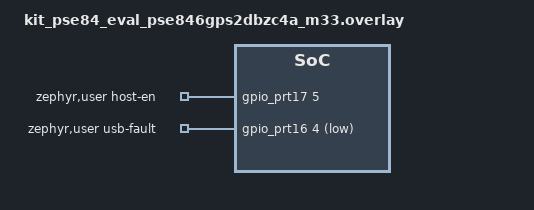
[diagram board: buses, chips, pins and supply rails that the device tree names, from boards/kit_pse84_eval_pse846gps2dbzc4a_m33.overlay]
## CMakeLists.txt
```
# SPDX-License-Identifier: Apache-2.0

cmake_minimum_required(VERSION 3.20.0)

find_package(Zephyr REQUIRED HINTS $ENV{ZEPHYR_BASE})
project(tinyusb_host_cdc_msc_hid)

# Application sources. This sample is fully Zephyr-native: the USBHS controller
# interrupt is connected by the ifx-tinyusb module
target_sources(app PRIVATE
  src/main.c
  src/cdc_app.c
  src/hid_app.c
  src/msc_app.c
)

target_include_directories(app PRIVATE
  src
)

# tusb_config.h lives in this sample's src/. It must also be visible to the
# TinyUSB module sources, which are compiled in the module's own CMake scope,
# so expose it on the global include path.
zephyr_include_directories(${CMAKE_CURRENT_SOURCE_DIR}/src)
```

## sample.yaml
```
sample:
  description: TinyUSB host CDC/MSC/HID example
  name: tinyusb host cdc_msc_hid
common:
  tags:
    - usb
    - tinyusb
    - host
    - samples
  modules:
    - tinyusb
tests:
  sample.usb.tinyusb.host.cdc_msc_hid:
    harness: none
    platform_allow:
      - kit_pse84_eval/pse846gps2dbzc4a/m33
    integration_platforms:
      - kit_pse84_eval/pse846gps2dbzc4a/m33
```

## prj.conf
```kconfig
# TinyUSB host example: CDC + MSC + HID
#
# Drives the TinyUSB Zephyr module (CONFIG_TINYUSB). The tusb_config.h in src/
# selects the host classes; the controller port is selected by Kconfig.

# Enable the TinyUSB module and the Infineon DWC2 (PSE84 high-speed) port.
CONFIG_TINYUSB=y
CONFIG_TINYUSB_PORT_DWC2_IFX=y

# Let the TinyUSB module connect the USBHS controller interrupt from devicetree
CONFIG_TINYUSB_DWC2_IFX_IRQ_CONNECT=y

CONFIG_GPIO=y
CONFIG_FPU=y

# The class app tasks run in the main thread (tuh_task() has its own thread);
# give the main stack headroom for descriptor parsing and control transfers.
CONFIG_MAIN_STACK_SIZE=4096
```

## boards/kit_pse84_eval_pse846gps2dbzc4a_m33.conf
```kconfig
# PSE84 secure m33 - TinyUSB provides its own host stack, so keep Zephyr's USB
# host/device stacks and their controller drivers disabled to avoid claiming
# the usbhs (DWC2) controller.
CONFIG_USB_HOST_STACK=n
CONFIG_UHC_DRIVER=n
CONFIG_USB_DEVICE_STACK=n
CONFIG_UDC_DRIVER=n
```

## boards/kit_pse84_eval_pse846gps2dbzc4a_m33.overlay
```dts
/*
 * KIT_PSE84_EVAL USB Host (Type-A connector J27) control signals.
 *
 * USB_HOST_EN (P17[5]) gates the USB mux (U25) and the VBUS_HOST power switch
 * (U21/U22). Driving it high switches the data lines to J27 and turns on the
 * 5V host VBUS. USB_FAULT (P16[4], active-low) flags a host VBUS overcurrent.
 *
 * The PSE84 GPIO port controllers are disabled by default, so enable the ports
 * used here and expose the pins to main.c through the zephyr,user node.
 */
#include <zephyr/dt-bindings/gpio/gpio.h>

&gpio_prt16 {
	status = "okay";
};

&gpio_prt17 {
	status = "okay";
};

/ {
	zephyr,user {
		host-en-gpios = <&gpio_prt17 5 GPIO_ACTIVE_HIGH>;
		usb-fault-gpios = <&gpio_prt16 4 GPIO_ACTIVE_LOW>;
	};
};
```

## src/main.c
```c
/*
 * The MIT License (MIT)
 *
 * Copyright (c) 2019 Ha Thach (tinyusb.org)
 *
 * Permission is hereby granted, free of charge, to any person obtaining a copy
 * of this software and associated documentation files (the "Software"), to deal
 * in the Software without restriction, including without limitation the rights
 * to use, copy, modify, merge, publish, distribute, sublicense, and/or sell
 * copies of the Software, and to permit persons to whom the Software is
 * furnished to do so, subject to the following conditions:
 *
 * The above copyright notice and this permission notice shall be included in
 * all copies or substantial portions of the Software.
 *
 * THE SOFTWARE IS PROVIDED "AS IS", WITHOUT WARRANTY OF ANY KIND, EXPRESS OR
 * IMPLIED, INCLUDING BUT NOT LIMITED TO THE WARRANTIES OF MERCHANTABILITY,
 * FITNESS FOR A PARTICULAR PURPOSE AND NONINFRINGEMENT. IN NO EVENT SHALL THE
 * AUTHORS OR COPYRIGHT HOLDERS BE LIABLE FOR ANY CLAIM, DAMAGES OR OTHER
 * LIABILITY, WHETHER IN AN ACTION OF CONTRACT, TORT OR OTHERWISE, ARISING FROM,
 * OUT OF OR IN CONNECTION WITH THE SOFTWARE OR THE USE OR OTHER DEALINGS IN
 * THE SOFTWARE.
 *
 */

#include <stdio.h>

#include "tusb.h"
#include "app.h"

#include <zephyr/kernel.h>
#include <zephyr/devicetree.h>
#include <zephyr/drivers/gpio.h>

//--------------------------------------------------------------------+
// MACRO CONSTANT TYPEDEF PROTOTYPES
//--------------------------------------------------------------------+
void led_blinking_task(void);

// Run tuh_task() in a dedicated COOPERATIVE (higher-than-main) thread so the
// host event queue is drained promptly even while the main thread is busy in
// blocking console printf (Zephyr uart_poll_out busy-waits and does not yield).
#define USB_HOST_STACK_SIZE 3072
static K_THREAD_STACK_DEFINE(usb_host_stack, USB_HOST_STACK_SIZE);
static struct k_thread usb_host_thread_data;

static void usb_host_thread(void *p1, void *p2, void *p3) {
  (void) p1; (void) p2; (void) p3;

  // Init the host stack on the configured roothub port.
  tusb_rhport_init_t host_init = {
    .role = TUSB_ROLE_HOST,
    .speed = TUSB_SPEED_AUTO
  };
  tusb_init(BOARD_TUH_RHPORT, &host_init);

  while (1) {
    tuh_task(); // blocks on the host event queue; wakes on USB events
  }
}

int main(void) {
  board_init();

  printf("TinyUSB Host CDC MSC HID Example\r\n");

  k_thread_create(&usb_host_thread_data, usb_host_stack,
                  K_THREAD_STACK_SIZEOF(usb_host_stack),
                  usb_host_thread, NULL, NULL, NULL,
                  K_PRIO_COOP(4), 0, K_NO_WAIT);
  k_thread_name_set(&usb_host_thread_data, "tuh_task");

  // Wait for the host stack to come up before running the app tasks.
  while (!tuh_inited()) {
    k_msleep(1);
  }

  while (1) {
    // Class app tasks + LED run in the main thread; the host thread owns
    // tuh_task(). The cooperative host thread preempts main on USB events, so
    // the event queue is drained even while these tasks block in printf.
    led_blinking_task();
    cdc_app_task();
    hid_app_task();
    k_msleep(1);
  }
}

//--------------------------------------------------------------------+
// TinyUSB Callbacks
//--------------------------------------------------------------------+

void tuh_mount_cb(uint8_t dev_addr) {
  // application set-up
  printf("A device with address %u is mounted\r\n", dev_addr);
}

void tuh_umount_cb(uint8_t dev_addr) {
  // application tear-down
  printf("A device with address %u is unmounted \r\n", dev_addr);
}


//--------------------------------------------------------------------+
// Blinking Task
//--------------------------------------------------------------------+
void led_blinking_task(void) {
  const uint32_t interval_ms = 1000;
  static uint32_t start_ms = 0;

  static bool led_state = false;

  // Blink every interval ms
  if (tusb_time_millis_api() - start_ms < interval_ms) {
    return;// not enough time
  }
  start_ms += interval_ms;

  board_led_write(led_state);
  led_state = 1 - led_state; // toggle
}

//--------------------------------------------------------------------+
// Board glue (Zephyr-native; replaces the TinyUSB hw/bsp board layer)
//--------------------------------------------------------------------+
static const struct gpio_dt_spec led = GPIO_DT_SPEC_GET_OR(DT_ALIAS(led0), gpios, {0});

#if CFG_TUH_ENABLED
// KIT_PSE84_EVAL routes the USB Host signals (Type-A connector J27) through a
// mux (U25) and a VBUS power switch (U21/U22), both gated by USB_HOST_EN
// (P17[5]). The pin is low by default (device USB connected, host VBUS off);
// firmware must drive it high to switch the mux to J27 and enable 5V VBUS_HOST.
// USB_FAULT (P16[4], active-low) reports host VBUS overcurrent. Both pins come
// from the sample's board overlay via the zephyr,user node.
static const struct gpio_dt_spec usb_host_en = GPIO_DT_SPEC_GET_OR(DT_PATH(zephyr_user), host_en_gpios, {0});
static const struct gpio_dt_spec usb_fault = GPIO_DT_SPEC_GET_OR(DT_PATH(zephyr_user), usb_fault_gpios, {0});
#endif

void board_init(void) {
  // LED
  if (gpio_is_ready_dt(&led)) {
    gpio_pin_configure_dt(&led, GPIO_OUTPUT_INACTIVE);
  }

#if CFG_TUH_ENABLED
  // Enable the USB Host path: drive USB_HOST_EN high (switches mux U25 to J27
  // and turns on VBUS_HOST). Without this the host port is disconnected and
  // unpowered, so no device can be enumerated.
  if (gpio_is_ready_dt(&usb_host_en)) {
    gpio_pin_configure_dt(&usb_host_en, GPIO_OUTPUT_ACTIVE);
  }
  // USB_FAULT is an input (active-low overcurrent flag); configure for reading.
  if (gpio_is_ready_dt(&usb_fault)) {
    gpio_pin_configure_dt(&usb_fault, GPIO_INPUT);
  }
#endif
}

void board_led_write(bool state) {
  if (gpio_is_ready_dt(&led)) {
    gpio_pin_set_dt(&led, state ? 1 : 0);
  }
}
```

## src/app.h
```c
/*
 * The MIT License (MIT)
 *
 * Copyright (c) 2025 Ha Thach (tinyusb.org)
 *
 * Permission is hereby granted, free of charge, to any person obtaining a copy
 * of this software and associated documentation files (the "Software"), to deal
 * in the Software without restriction, including without limitation the rights
 * to use, copy, modify, merge, publish, distribute, sublicense, and/or sell
 * copies of the Software, and to permit persons to whom the Software is
 * furnished to do so, subject to the following conditions:
 *
 * The above copyright notice and this permission notice shall be included in
 * all copies or substantial portions of the Software.
 *
 * THE SOFTWARE IS PROVIDED "AS IS", WITHOUT WARRANTY OF ANY KIND, EXPRESS OR
 * IMPLIED, INCLUDING BUT NOT LIMITED TO THE WARRANTIES OF MERCHANTABILITY,
 * FITNESS FOR A PARTICULAR PURPOSE AND NONINFRINGEMENT. IN NO EVENT SHALL THE
 * AUTHORS OR COPYRIGHT HOLDERS BE LIABLE FOR ANY CLAIM, DAMAGES OR OTHER
 * LIABILITY, WHETHER IN AN ACTION OF CONTRACT, TORT OR OTHERWISE, ARISING FROM,
 * OUT OF OR IN CONNECTION WITH THE SOFTWARE OR THE USE OR OTHER DEALINGS IN
 * THE SOFTWARE.
 *
 * This file is part of the TinyUSB stack.
 */
#ifndef TUSB_TINYUSB_EXAMPLES_APP_H
#define TUSB_TINYUSB_EXAMPLES_APP_H

#include <stdbool.h>
#include <stdio.h>

void cdc_app_task(void);
void hid_app_task(void);

// Minimal board glue implemented in main.c
void board_init(void);
void board_led_write(bool state);

#endif
```

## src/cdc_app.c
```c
/*
 * The MIT License (MIT)
 *
 * Copyright (c) 2022, Ha Thach (tinyusb.org)
 *
 * Permission is hereby granted, free of charge, to any person obtaining a copy
 * of this software and associated documentation files (the "Software"), to deal
 * in the Software without restriction, including without limitation the rights
 * to use, copy, modify, merge, publish, distribute, sublicense, and/or sell
 * copies of the Software, and to permit persons to whom the Software is
 * furnished to do so, subject to the following conditions:
 *
 * The above copyright notice and this permission notice shall be included in
 * all copies or substantial portions of the Software.
 *
 * THE SOFTWARE IS PROVIDED "AS IS", WITHOUT WARRANTY OF ANY KIND, EXPRESS OR
 * IMPLIED, INCLUDING BUT NOT LIMITED TO THE WARRANTIES OF MERCHANTABILITY,
 * FITNESS FOR A PARTICULAR PURPOSE AND NONINFRINGEMENT. IN NO EVENT SHALL THE
 * AUTHORS OR COPYRIGHT HOLDERS BE LIABLE FOR ANY CLAIM, DAMAGES OR OTHER
 * LIABILITY, WHETHER IN AN ACTION OF CONTRACT, TORT OR OTHERWISE, ARISING FROM,
 * OUT OF OR IN CONNECTION WITH THE SOFTWARE OR THE USE OR OTHER DEALINGS IN
 * THE SOFTWARE.
 *
 * This file is part of the TinyUSB stack.
 */

#include "tusb.h"
#include "app.h"

void cdc_app_task(void) {
  const uint8_t idx = 0;

  if (!tuh_cdc_mounted(idx)) {
    return;
  }

  // Drain data from the device. This port has no console bridge, so the bytes
  // are discarded; reading keeps the CDC RX pipe from stalling.
  uint8_t buf[64];
  tuh_cdc_read(idx, buf, sizeof(buf));
}

//--------------------------------------------------------------------+
// TinyUSB callbacks
//--------------------------------------------------------------------+

// Invoked when a device with CDC interface is mounted
// idx is index of cdc interface in the internal pool.
void tuh_cdc_mount_cb(uint8_t idx) {
  tuh_itf_info_t itf_info = {0};
  tuh_cdc_itf_get_info(idx, &itf_info);

  printf("CDC Interface is mounted: address = %u, itf_num = %u\r\n", itf_info.daddr,
         itf_info.desc.bInterfaceNumber);

  // If CFG_TUH_CDC_LINE_CODING_ON_ENUM is defined, line coding will be set by tinyusb stack
  // while eneumerating new cdc device
  cdc_line_coding_t line_coding = {0};
  if (tuh_cdc_get_line_coding_local(idx, &line_coding)) {
    printf("  Baudrate: %" PRIu32 ", Stop Bits : %u\r\n", line_coding.bit_rate, line_coding.stop_bits);
    printf("  Parity  : %u, Data Width: %u\r\n", line_coding.parity, line_coding.data_bits);
  }
}

// Invoked when a device with CDC interface is unmounted
void tuh_cdc_umount_cb(uint8_t idx) {
  tuh_itf_info_t itf_info = {0};
  tuh_cdc_itf_get_info(idx, &itf_info);

  printf("CDC Interface is unmounted: address = %u, itf_num = %u\r\n", itf_info.daddr,
         itf_info.desc.bInterfaceNumber);
}
```

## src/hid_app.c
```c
/*
 * The MIT License (MIT)
 *
 * Copyright (c) 2019 Ha Thach (tinyusb.org)
 *
 * Permission is hereby granted, free of charge, to any person obtaining a copy
 * of this software and associated documentation files (the "Software"), to deal
 * in the Software without restriction, including without limitation the rights
 * to use, copy, modify, merge, publish, distribute, sublicense, and/or sell
 * copies of the Software, and to permit persons to whom the Software is
 * furnished to do so, subject to the following conditions:
 *
 * The above copyright notice and this permission notice shall be included in
 * all copies or substantial portions of the Software.
 *
 * THE SOFTWARE IS PROVIDED "AS IS", WITHOUT WARRANTY OF ANY KIND, EXPRESS OR
 * IMPLIED, INCLUDING BUT NOT LIMITED TO THE WARRANTIES OF MERCHANTABILITY,
 * FITNESS FOR A PARTICULAR PURPOSE AND NONINFRINGEMENT. IN NO EVENT SHALL THE
 * AUTHORS OR COPYRIGHT HOLDERS BE LIABLE FOR ANY CLAIM, DAMAGES OR OTHER
 * LIABILITY, WHETHER IN AN ACTION OF CONTRACT, TORT OR OTHERWISE, ARISING FROM,
 * OUT OF OR IN CONNECTION WITH THE SOFTWARE OR THE USE OR OTHER DEALINGS IN
 * THE SOFTWARE.
 *
 */
#include "tusb.h"
#include "app.h"

//--------------------------------------------------------------------+
// MACRO TYPEDEF CONSTANT ENUM DECLARATION
//--------------------------------------------------------------------+
#define MAX_REPORT 4

static uint8_t const keycode2ascii[128][2] = {HID_KEYCODE_TO_ASCII};

// Each HID instance can has multiple reports
static struct {
  uint8_t report_count;
  tuh_hid_report_info_t report_info[MAX_REPORT];
} hid_info[CFG_TUH_HID];

static void process_kbd_report(hid_keyboard_report_t const *report);
static void process_mouse_report(hid_mouse_report_t const *report);
static void process_generic_report(uint8_t dev_addr, uint8_t instance, uint8_t const *report, uint16_t len);

void hid_app_task(void) {
  // nothing to do
}

//--------------------------------------------------------------------+
// TinyUSB Callbacks
//--------------------------------------------------------------------+

// Invoked when device with hid interface is mounted
// Report descriptor is also available for use. tuh_hid_parse_report_descriptor()
// can be used to parse common/simple enough descriptor.
// Note: if report descriptor length > CFG_TUH_ENUMERATION_BUFSIZE, it will be skipped
// therefore report_desc = NULL, desc_len = 0
void tuh_hid_mount_cb(uint8_t dev_addr, uint8_t instance, uint8_t const *desc_report, uint16_t desc_len) {
  printf("HID device address = %d, instance = %d is mounted\r\n", dev_addr, instance);

  // Interface protocol (hid_interface_protocol_enum_t)
  const char *protocol_str[] = {"None", "Keyboard", "Mouse"};
  uint8_t const itf_protocol = tuh_hid_interface_protocol(dev_addr, instance);

  printf("HID Interface Protocol = %s\r\n", protocol_str[itf_protocol]);

  // By default, host stack will use boot protocol on supported interface.
  // Therefore for this simple example, we only need to parse generic report descriptor (with built-in parser)
  if (itf_protocol == HID_ITF_PROTOCOL_NONE) {
    hid_info[instance].report_count = tuh_hid_parse_report_descriptor(hid_info[instance].report_info, MAX_REPORT, desc_report, desc_len);
    printf("HID has %u reports \r\n", hid_info[instance].report_count);
  }

  // request to receive report
  // tuh_hid_report_received_cb() will be invoked when report is available
  if (!tuh_hid_receive_report(dev_addr, instance)) {
    printf("Error: cannot request to receive report\r\n");
  }
}

// Invoked when device with hid interface is un-mounted
void tuh_hid_umount_cb(uint8_t dev_addr, uint8_t instance) {
  printf("HID device address = %d, instance = %d is unmounted\r\n", dev_addr, instance);
}

// Invoked when received report from device via interrupt endpoint
void tuh_hid_report_received_cb(uint8_t dev_addr, uint8_t instance, uint8_t const *report, uint16_t len) {
  uint8_t const itf_protocol = tuh_hid_interface_protocol(dev_addr, instance);

  switch (itf_protocol) {
    case HID_ITF_PROTOCOL_KEYBOARD:
      TU_LOG2("HID receive boot keyboard report\r\n");
      process_kbd_report((hid_keyboard_report_t const *) report);
      break;

    case HID_ITF_PROTOCOL_MOUSE:
      TU_LOG2("HID receive boot mouse report\r\n");
      process_mouse_report((hid_mouse_report_t const *) report);
      break;

    default:
      // Generic report requires matching ReportID and contents with previous parsed report info
      process_generic_report(dev_addr, instance, report, len);
      break;
  }

  // continue to request to receive report
  if (!tuh_hid_receive_report(dev_addr, instance)) {
    printf("Error: cannot request to receive report\r\n");
  }
}

//--------------------------------------------------------------------+
// Keyboard
//--------------------------------------------------------------------+

// look up new key in previous keys
static inline bool find_key_in_report(hid_keyboard_report_t const *report, uint8_t keycode) {
  for (uint8_t i = 0; i < 6; i++) {
    if (report->keycode[i] == keycode) {
      return true;
    }
  }
  return false;
}

static void process_kbd_report(hid_keyboard_report_t const *report) {
  static hid_keyboard_report_t prev_report = {0, 0, {0}};// previous report to check key released

  //------------- example code ignore control (non-printable) key affects -------------//
  for (uint8_t i = 0; i < 6; i++) {
    if (report->keycode[i]) {
      if (find_key_in_report(&prev_report, report->keycode[i])) {
        // exist in previous report means the current key is holding
      } else {
        // not existed in previous report means the current key is pressed
        bool const is_shift = report->modifier & (KEYBOARD_MODIFIER_LEFTSHIFT | KEYBOARD_MODIFIER_RIGHTSHIFT);
        uint8_t ch = keycode2ascii[report->keycode[i]][is_shift ? 1 : 0];
        putchar(ch);
        if (ch == '\r') {
          putchar('\n');
        }

        #ifndef __ICCARM__     // TODO IAR doesn't support stream control ?
        fflush(stdout);// flush right away, else nanolib will wait for newline
        #endif
      }
    }
    // TODO example skips key released
  }

  prev_report = *report;
}

//--------------------------------------------------------------------+
// Mouse
//--------------------------------------------------------------------+

static void cursor_movement(int8_t x, int8_t y, int8_t wheel) {
  printf("(%d %d %d)\r\n", x, y, wheel);
}

static void process_mouse_report(hid_mouse_report_t const *report) {
  static hid_mouse_report_t prev_report = {0};

  // button state
  uint8_t button_changed_mask = report->buttons ^ prev_report.buttons;
  if (button_changed_mask & report->buttons) {
    printf(" %c%c%c ",
           report->buttons & MOUSE_BUTTON_LEFT ? 'L' : '-',
           report->buttons & MOUSE_BUTTON_MIDDLE ? 'M' : '-',
           report->buttons & MOUSE_BUTTON_RIGHT ? 'R' : '-');
  }

  // cursor movement
  cursor_movement(report->x, report->y, report->wheel);
}

//--------------------------------------------------------------------+
// Generic Report
//--------------------------------------------------------------------+
static void process_generic_report(uint8_t dev_addr, uint8_t instance, uint8_t const *report, uint16_t len) {
  (void) dev_addr;
  (void) len;

  uint8_t const rpt_count = hid_info[instance].report_count;
  tuh_hid_report_info_t *rpt_info_arr = hid_info[instance].report_info;
  tuh_hid_report_info_t *rpt_info = NULL;

  if (rpt_count == 1 && rpt_info_arr[0].report_id == 0) {
    // Simple report without report ID as 1st byte
    rpt_info = &rpt_info_arr[0];
  } else {
    // Composite report, 1st byte is report ID, data starts from 2nd byte
    uint8_t const rpt_id = report[0];

    // Find report id in the array
    for (uint8_t i = 0; i < rpt_count; i++) {
      if (rpt_id == rpt_info_arr[i].report_id) {
        rpt_info = &rpt_info_arr[i];
        break;
      }
    }

    report++;
    len--;
  }

  if (!rpt_info) {
    printf("Couldn't find report info !\r\n");
    return;
  }

  // For complete list of Usage Page & Usage checkout src/class/hid/hid.h. For examples:
  // - Keyboard                     : Desktop, Keyboard
  // - Mouse                        : Desktop, Mouse
  // - Gamepad                      : Desktop, Gamepad
  // - Consumer Control (Media Key) : Consumer, Consumer Control
  // - System Control (Power key)   : Desktop, System Control
  // - Generic (vendor)             : 0xFFxx, xx
  if (rpt_info->usage_page == HID_USAGE_PAGE_DESKTOP) {
    switch (rpt_info->usage) {
      case HID_USAGE_DESKTOP_KEYBOARD:
        TU_LOG2("HID receive keyboard report\r\n");
        // Assume keyboard follow boot report layout
        process_kbd_report((hid_keyboard_report_t const *) report);
        break;

      case HID_USAGE_DESKTOP_MOUSE:
        TU_LOG2("HID receive mouse report\r\n");
        // Assume mouse follow boot report layout
        process_mouse_report((hid_mouse_report_t const *) report);
        break;

      default:
        printf("report[%u] ", rpt_info->report_id);
        for (uint8_t i = 0; i < len; i++) {
          printf("%02X ", report[i]);
        }
        printf("\r\n");
        break;
    }
  }
}
```
